# MSP432P411V register map
Vendor: Texas Instruments; File version: 3.230
Registers are 32-bit, read-write, reset 0x0 unless marked. A register's access mark holds for its fields unless they carry their own. Offsets are from the block's base; [hi:lo] are bit positions.

## PMAP
Base 0x40005000
0x00 PMAPKEYID 16-bit reset 0x96A5 — Port Mapping Key Register
  [15:0] PMAPKEY — Port mapping controller write access key
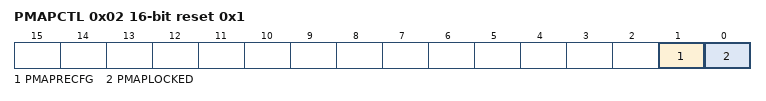
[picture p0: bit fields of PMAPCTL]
0x02 PMAPCTL 16-bit reset 0x1 — Port Mapping Control Register
  [1] PMAPRECFG — Port mapping reconfiguration control bit
    0=Configuration allowed only once; 1=Allow reconfiguration of port mapping
  [0] PMAPLOCKED ro — Port mapping lock bit
    on read: 0=Access to mapping registers is granted; 1=Access to mapping registers is locked
0x08 P1MAP01 16-bit reset not defined — Port mapping register, P1.0 and P1.1
  [15:0] PMAPx — Selects secondary port function
0x0A P1MAP23 16-bit reset not defined — Port mapping register, P1.2 and P1.3
  [15:0] PMAPx — Selects secondary port function
0x0C P1MAP45 16-bit reset not defined — Port mapping register, P1.4 and P1.5
  [15:0] PMAPx — Selects secondary port function
0x0E P1MAP67 16-bit reset not defined — Port mapping register, P1.6 and P1.7
  [15:0] PMAPx — Selects secondary port function
0x10 P2MAP01 16-bit reset not defined — Port mapping register, P2.0 and P2.1
  [15:0] PMAPx — Selects secondary port function
0x12 P2MAP23 16-bit reset not defined — Port mapping register, P2.2 and P2.3
  [15:0] PMAPx — Selects secondary port function
0x14 P2MAP45 16-bit reset not defined — Port mapping register, P2.4 and P2.5
  [15:0] PMAPx — Selects secondary port function
0x16 P2MAP67 16-bit reset not defined — Port mapping register, P2.6 and P2.7
  [15:0] PMAPx — Selects secondary port function
0x18 P3MAP01 16-bit reset not defined — Port mapping register, P3.0 and P3.1
  [15:0] PMAPx — Selects secondary port function
0x1A P3MAP23 16-bit reset not defined — Port mapping register, P3.2 and P3.3
  [15:0] PMAPx — Selects secondary port function
0x1C P3MAP45 16-bit reset not defined — Port mapping register, P3.4 and P3.5
  [15:0] PMAPx — Selects secondary port function
0x1E P3MAP67 16-bit reset not defined — Port mapping register, P3.6 and P3.7
  [15:0] PMAPx — Selects secondary port function
0x20 P4MAP01 16-bit reset not defined — Port mapping register, P4.0 and P4.1
  [15:0] PMAPx — Selects secondary port function
0x22 P4MAP23 16-bit reset not defined — Port mapping register, P4.2 and P4.3
  [15:0] PMAPx — Selects secondary port function
0x24 P4MAP45 16-bit reset not defined — Port mapping register, P4.4 and P4.5
  [15:0] PMAPx — Selects secondary port function
0x26 P4MAP67 16-bit reset not defined — Port mapping register, P4.6 and P4.7
  [15:0] PMAPx — Selects secondary port function
0x28 P5MAP01 16-bit reset not defined — Port mapping register, P5.0 and P5.1
  [15:0] PMAPx — Selects secondary port function
0x2A P5MAP23 16-bit reset not defined — Port mapping register, P5.2 and P5.3
  [15:0] PMAPx — Selects secondary port function
0x2C P5MAP45 16-bit reset not defined — Port mapping register, P5.4 and P5.5
  [15:0] PMAPx — Selects secondary port function
0x2E P5MAP67 16-bit reset not defined — Port mapping register, P5.6 and P5.7
  [15:0] PMAPx — Selects secondary port function
0x30 P6MAP01 16-bit reset not defined — Port mapping register, P6.0 and P6.1
  [15:0] PMAPx — Selects secondary port function
0x32 P6MAP23 16-bit reset not defined — Port mapping register, P6.2 and P6.3
  [15:0] PMAPx — Selects secondary port function
0x34 P6MAP45 16-bit reset not defined — Port mapping register, P6.4 and P6.5
  [15:0] PMAPx — Selects secondary port function
0x36 P6MAP67 16-bit reset not defined — Port mapping register, P6.6 and P6.7
  [15:0] PMAPx — Selects secondary port function
0x38 P7MAP01 16-bit reset not defined — Port mapping register, P7.0 and P7.1
  [15:0] PMAPx — Selects secondary port function
0x3A P7MAP23 16-bit reset not defined — Port mapping register, P7.2 and P7.3
  [15:0] PMAPx — Selects secondary port function
0x3C P7MAP45 16-bit reset not defined — Port mapping register, P7.4 and P7.5
  [15:0] PMAPx — Selects secondary port function
0x3E P7MAP67 16-bit reset not defined — Port mapping register, P7.6 and P7.7
  [15:0] PMAPx — Selects secondary port function

## Notices in the file
Copyright (C) 2012-2018 Texas Instruments Incorporated - http://www.ti.com
Redistribution and use in source and binary forms, with or without
modification, are permitted provided that the following conditions
are met:
Redistributions of source code must retain the above copyright
notice, this list of conditions and the following disclaimer.
Redistributions in binary form must reproduce the above copyright
notice, this list of conditions and the following disclaimer in the
documentation and/or other materials provided with the
distribution.
Neither the name of Texas Instruments Incorporated nor the names of
its contributors may be used to endorse or promote products derived
from this software without specific prior written permission.
THIS SOFTWARE IS PROVIDED BY THE COPYRIGHT HOLDERS AND CONTRIBUTORS
"AS IS" AND ANY EXPRESS OR IMPLIED WARRANTIES, INCLUDING, BUT NOT
LIMITED TO, THE IMPLIED WARRANTIES OF MERCHANTABILITY AND FITNESS FOR
A PARTICULAR PURPOSE ARE DISCLAIMED. IN NO EVENT SHALL THE COPYRIGHT
OWNER OR CONTRIBUTORS BE LIABLE FOR ANY DIRECT, INDIRECT, INCIDENTAL,
SPECIAL, EXEMPLARY, OR CONSEQUENTIAL DAMAGES (INCLUDING, BUT NOT
LIMITED TO, PROCUREMENT OF SUBSTITUTE GOODS OR SERVICES; LOSS OF USE,
DATA, OR PROFITS; OR BUSINESS INTERRUPTION) HOWEVER CAUSED AND ON ANY
THEORY OF LIABILITY, WHETHER IN CONTRACT, STRICT LIABILITY, OR TORT
(INCLUDING NEGLIGENCE OR OTHERWISE) ARISING IN ANY WAY OUT OF THE USE
OF THIS SOFTWARE, EVEN IF ADVISED OF THE POSSIBILITY OF SUCH DAMAGE.
